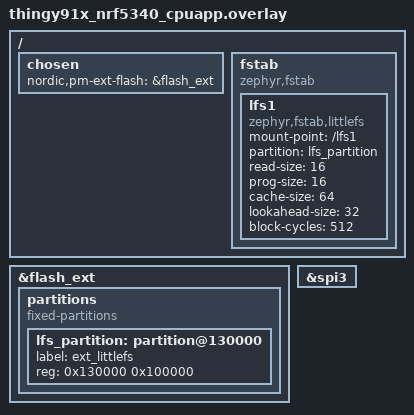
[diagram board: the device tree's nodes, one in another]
/* Copyright (c) 2024 Nordic Semiconductor ASA
 *
 * SPDX-License-Identifier: LicenseRef-Nordic-5-Clause
 */

/* modified to use external flash */

&flash_ext {
        status = "okay";
        partitions {
        compatible = "fixed-partitions";
        #address-cells = <1>;
        #size-cells = <1>;

        /* Place LittleFS in external flash */
        lfs_partition: partition@130000 {
            label = "ext_littlefs";
            reg = <0x130000 0x100000>; /* 1MB of external flash for LittleFS */
        };
    };
};

&spi3 {
	status = "okay";
};

/ {
	chosen {
		nordic,pm-ext-flash = &flash_ext;
	};

    fstab {
        compatible = "zephyr,fstab";
        lfs1: lfs1 {
            compatible = "zephyr,fstab,littlefs";
            mount-point = "/lfs1";
            partition = <&lfs_partition>;
            read-size = <16>;
            prog-size = <16>;
            cache-size = <64>;
            lookahead-size = <32>;
            block-cycles = <512>;
        };
    };
};
